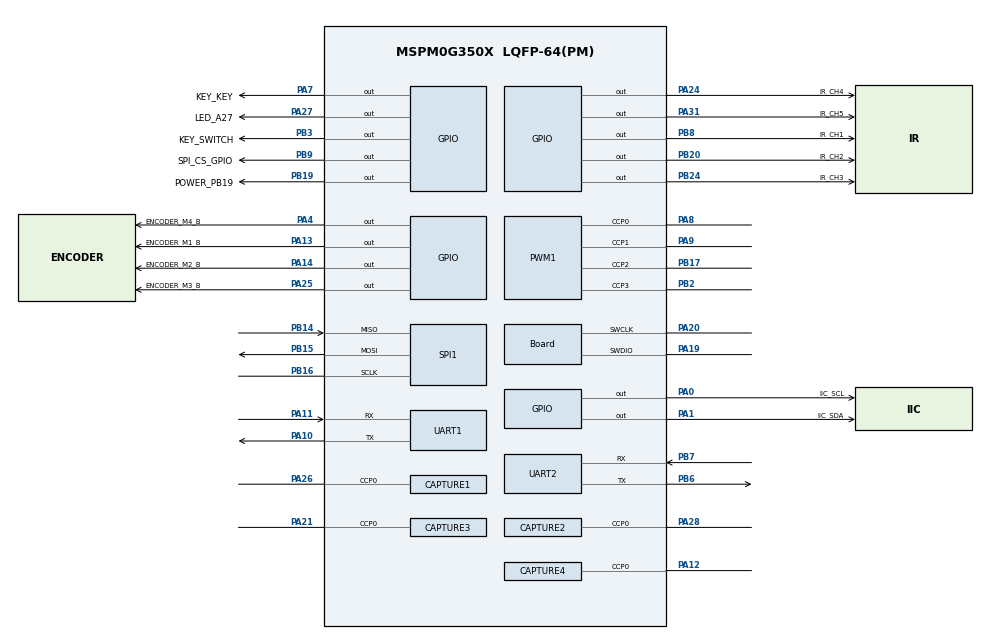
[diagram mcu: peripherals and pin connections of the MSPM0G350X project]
/**
 *
 * @cliArgs --device "MSPM0G350X" --part "Default" --package "LQFP-64(PM)" --product "mspm0_sdk@2.11.00.07"
 * @versions {"tool":"1.28.0+4712"}
 */

/**
 * Import the modules used in this configuration.
 */
const CAPTURE  = scripting.addModule("/ti/driverlib/CAPTURE", {}, false);
const CAPTURE1 = CAPTURE.addInstance();
const CAPTURE2 = CAPTURE.addInstance();
const CAPTURE3 = CAPTURE.addInstance();
const CAPTURE4 = CAPTURE.addInstance();
const GPIO     = scripting.addModule("/ti/driverlib/GPIO", {}, false);
const GPIO1    = GPIO.addInstance();
const GPIO2    = GPIO.addInstance();
const GPIO3    = GPIO.addInstance();
const GPIO4    = GPIO.addInstance();
const GPIO5    = GPIO.addInstance();
const PWM      = scripting.addModule("/ti/driverlib/PWM", {}, false);
const PWM1     = PWM.addInstance();
const SPI      = scripting.addModule("/ti/driverlib/SPI", {}, false);
const SPI1     = SPI.addInstance();
const TIMER    = scripting.addModule("/ti/driverlib/TIMER", {}, false);
const TIMER1   = TIMER.addInstance();
const UART     = scripting.addModule("/ti/driverlib/UART", {}, false);
const UART1    = UART.addInstance();
const UART2    = UART.addInstance();

/**
 * Write custom configuration values to the imported modules.
 */
const pinFunction4     = system.clockTree["HFXT"];
pinFunction4.inputFreq = 8;
pinFunction4.enable    = true;

CAPTURE1.$name                              = "M3";
CAPTURE1.peripheral.$assign                 = "TIMG7";
CAPTURE1.peripheral.ccp0Pin.$assign         = "PA26";
CAPTURE1.ccp0PinConfig.$name                = "ti_driverlib_gpio_GPIOPinGeneric1";
CAPTURE1.ccp0PinConfig.hideOutputInversion  = scripting.forceWrite(false);
CAPTURE1.ccp0PinConfig.onlyInternalResistor = scripting.forceWrite(false);
CAPTURE1.ccp0PinConfig.passedPeripheralType = scripting.forceWrite("Digital");

const Board                       = scripting.addModule("/ti/driverlib/Board", {}, false);
Board.peripheral.$assign          = "DEBUGSS";
Board.peripheral.swclkPin.$assign = "PA20";
Board.peripheral.swdioPin.$assign = "PA19";

CAPTURE2.$name                              = "M4";
CAPTURE2.peripheral.$assign                 = "TIMA1";
CAPTURE2.peripheral.ccp0Pin.$assign         = "PA28";
CAPTURE2.ccp0PinConfig.$name                = "ti_driverlib_gpio_GPIOPinGeneric2";
CAPTURE2.ccp0PinConfig.hideOutputInversion  = scripting.forceWrite(false);
CAPTURE2.ccp0PinConfig.onlyInternalResistor = scripting.forceWrite(false);
CAPTURE2.ccp0PinConfig.passedPeripheralType = scripting.forceWrite("Digital");

CAPTURE3.$name                              = "M2";
CAPTURE3.peripheral.$assign                 = "TIMG6";
CAPTURE3.peripheral.ccp0Pin.$assign         = "PA21";
CAPTURE3.ccp0PinConfig.$name                = "ti_driverlib_gpio_GPIOPinGeneric3";
CAPTURE3.ccp0PinConfig.hideOutputInversion  = scripting.forceWrite(false);
CAPTURE3.ccp0PinConfig.onlyInternalResistor = scripting.forceWrite(false);
CAPTURE3.ccp0PinConfig.passedPeripheralType = scripting.forceWrite("Digital");

CAPTURE4.$name                              = "M1";
CAPTURE4.peripheral.$assign                 = "TIMG0";
CAPTURE4.peripheral.ccp0Pin.$assign         = "PA12";
CAPTURE4.ccp0PinConfig.$name                = "ti_driverlib_gpio_GPIOPinGeneric4";
CAPTURE4.ccp0PinConfig.hideOutputInversion  = scripting.forceWrite(false);
CAPTURE4.ccp0PinConfig.onlyInternalResistor = scripting.forceWrite(false);
CAPTURE4.ccp0PinConfig.passedPeripheralType = scripting.forceWrite("Digital");

GPIO1.$name                         = "GPIO_LED";
GPIO1.associatedPins[0].$name       = "LED_A27";
GPIO1.associatedPins[0].pin.$assign = "PA27";

GPIO2.$name                         = "GPIO_ENCODERS";
GPIO2.associatedPins.create(4);
GPIO2.associatedPins[0].$name       = "ENCODER_M1_B";
GPIO2.associatedPins[0].pin.$assign = "PA13";
GPIO2.associatedPins[1].$name       = "ENCODER_M2_B";
GPIO2.associatedPins[1].pin.$assign = "PA14";
GPIO2.associatedPins[2].$name       = "ENCODER_M3_B";
GPIO2.associatedPins[2].pin.$assign = "PA25";
GPIO2.associatedPins[3].$name       = "ENCODER_M4_B";
GPIO2.associatedPins[3].pin.$assign = "PA4";

GPIO3.$name                         = "GPIO_SW_I2C";
GPIO3.associatedPins.create(2);
GPIO3.associatedPins[0].$name       = "IIC_SCL";
GPIO3.associatedPins[0].pin.$assign = "PA0";
GPIO3.associatedPins[1].$name       = "IIC_SDA";
GPIO3.associatedPins[1].pin.$assign = "PA1";

GPIO4.$name                         = "GPIO_CTRL";
GPIO4.associatedPins.create(4);
GPIO4.associatedPins[0].$name       = "SPI_CS_GPIO";
GPIO4.associatedPins[0].pin.$assign = "PB9";
GPIO4.associatedPins[1].$name       = "POWER_PB19";
GPIO4.associatedPins[1].pin.$assign = "PB19";
GPIO4.associatedPins[2].$name       = "KEY_KEY";
GPIO4.associatedPins[2].pin.$assign = "PA7";
GPIO4.associatedPins[3].$name       = "KEY_SWITCH";
GPIO4.associatedPins[3].pin.$assign = "PB3";

GPIO5.$name                         = "GPIO_IR";
GPIO5.associatedPins.create(5);
GPIO5.associatedPins[0].$name       = "IR_CH1";
GPIO5.associatedPins[0].pin.$assign = "PB8";
GPIO5.associatedPins[1].$name       = "IR_CH2";
GPIO5.associatedPins[1].pin.$assign = "PB20";
GPIO5.associatedPins[2].$name       = "IR_CH3";
GPIO5.associatedPins[2].pin.$assign = "PB24";
GPIO5.associatedPins[3].$name       = "IR_CH4";
GPIO5.associatedPins[3].pin.$assign = "PA24";
GPIO5.associatedPins[4].$name       = "IR_CH5";
GPIO5.associatedPins[4].pin.$assign = "PA31";

PWM1.$name                              = "PWM_MOTOR";
PWM1.ccIndex                            = [0,1,2,3];
PWM1.PWM_CHANNEL_0.$name                = "ti_driverlib_pwm_PWMTimerCC0";
PWM1.PWM_CHANNEL_1.$name                = "ti_driverlib_pwm_PWMTimerCC1";
PWM1.ccp0PinConfig.$name                = "ti_driverlib_gpio_GPIOPinGeneric5";
PWM1.ccp0PinConfig.direction            = scripting.forceWrite("OUTPUT");
PWM1.ccp0PinConfig.hideOutputInversion  = scripting.forceWrite(false);
PWM1.ccp0PinConfig.onlyInternalResistor = scripting.forceWrite(false);
PWM1.ccp0PinConfig.passedPeripheralType = scripting.forceWrite("Digital");
PWM1.ccp1PinConfig.$name                = "ti_driverlib_gpio_GPIOPinGeneric6";
PWM1.ccp1PinConfig.direction            = scripting.forceWrite("OUTPUT");
PWM1.ccp1PinConfig.hideOutputInversion  = scripting.forceWrite(false);
PWM1.ccp1PinConfig.onlyInternalResistor = scripting.forceWrite(false);
PWM1.ccp1PinConfig.passedPeripheralType = scripting.forceWrite("Digital");
PWM1.peripheral.$assign                 = "TIMA0";
PWM1.peripheral.ccp0Pin.$assign         = "PA8";
PWM1.peripheral.ccp1Pin.$assign         = "PA9";
PWM1.peripheral.ccp2Pin.$assign         = "PB17";
PWM1.peripheral.ccp3Pin.$assign         = "PB2";
PWM1.PWM_CHANNEL_2.$name                = "ti_driverlib_pwm_PWMTimerCC2";
PWM1.PWM_CHANNEL_3.$name                = "ti_driverlib_pwm_PWMTimerCC3";
PWM1.ccp2PinConfig.$name                = "ti_driverlib_gpio_GPIOPinGeneric7";
PWM1.ccp3PinConfig.$name                = "ti_driverlib_gpio_GPIOPinGeneric8";

SPI1.$name                                   = "SPI_0";
SPI1.peripheral.$assign                      = "SPI1";
SPI1.peripheral.sclkPin.$assign              = "PB16";
SPI1.peripheral.mosiPin.$assign              = "PB15";
SPI1.peripheral.misoPin.$assign              = "PB14";
SPI1.peripheral.cs0Pin.$assignAllowConflicts = "PA2";
SPI1.sclkPinConfig.$name                     = "ti_driverlib_gpio_GPIOPinGeneric9";
SPI1.mosiPinConfig.$name                     = "ti_driverlib_gpio_GPIOPinGeneric10";
SPI1.misoPinConfig.$name                     = "ti_driverlib_gpio_GPIOPinGeneric11";
SPI1.cs0PinConfig.$name                      = "ti_driverlib_gpio_GPIOPinGeneric12";

const SYSCTL       = scripting.addModule("/ti/driverlib/SYSCTL", {}, false);
SYSCTL.clockTreeEn = true;

TIMER1.$name              = "MyGPTIMER1";
TIMER1.timerPeriod        = "10 ms";
TIMER1.timerMode          = "PERIODIC";
TIMER1.interrupts         = ["ZERO"];
TIMER1.peripheral.$assign = "TIMG12";

UART1.$name                            = "UART_0_DEBUG";
UART1.peripheral.$assign               = "UART0";
UART1.peripheral.rxPin.$assign         = "PA11";
UART1.peripheral.txPin.$assign         = "PA10";
UART1.txPinConfig.$name                = "ti_driverlib_gpio_GPIOPinGeneric13";
UART1.txPinConfig.direction            = scripting.forceWrite("OUTPUT");
UART1.txPinConfig.hideOutputInversion  = scripting.forceWrite(false);
UART1.txPinConfig.onlyInternalResistor = scripting.forceWrite(false);
UART1.txPinConfig.passedPeripheralType = scripting.forceWrite("Digital");
UART1.rxPinConfig.$name                = "ti_driverlib_gpio_GPIOPinGeneric14";
UART1.rxPinConfig.hideOutputInversion  = scripting.forceWrite(false);
UART1.rxPinConfig.onlyInternalResistor = scripting.forceWrite(false);
UART1.rxPinConfig.passedPeripheralType = scripting.forceWrite("Digital");

UART2.$name                            = "UART1";
UART2.peripheral.$assign               = "UART1";
UART2.peripheral.rxPin.$assign         = "PB7";
UART2.peripheral.txPin.$assign         = "PB6";
UART2.txPinConfig.$name                = "ti_driverlib_gpio_GPIOPinGeneric15";
UART2.txPinConfig.direction            = scripting.forceWrite("OUTPUT");
UART2.txPinConfig.hideOutputInversion  = scripting.forceWrite(false);
UART2.txPinConfig.onlyInternalResistor = scripting.forceWrite(false);
UART2.txPinConfig.passedPeripheralType = scripting.forceWrite("Digital");
UART2.rxPinConfig.$name                = "ti_driverlib_gpio_GPIOPinGeneric16";
UART2.rxPinConfig.hideOutputInversion  = scripting.forceWrite(false);
UART2.rxPinConfig.onlyInternalResistor = scripting.forceWrite(false);
UART2.rxPinConfig.passedPeripheralType = scripting.forceWrite("Digital");

const ProjectConfig              = scripting.addModule("/ti/project_config/ProjectConfig", {}, false);
ProjectConfig.migrationCondition = true;

/**
 * Pinmux solution for unlocked pins/peripherals. This ensures that minor changes to the automatic solver in a future
 * version of the tool will not impact the pinmux you originally saw.  These lines can be completely deleted in order to
 * re-solve from scratch.
 */
pinFunction4.peripheral.$suggestSolution           = "SYSCTL";
pinFunction4.peripheral.hfxInPin.$suggestSolution  = "PA5";
pinFunction4.peripheral.hfxOutPin.$suggestSolution = "PA6";
